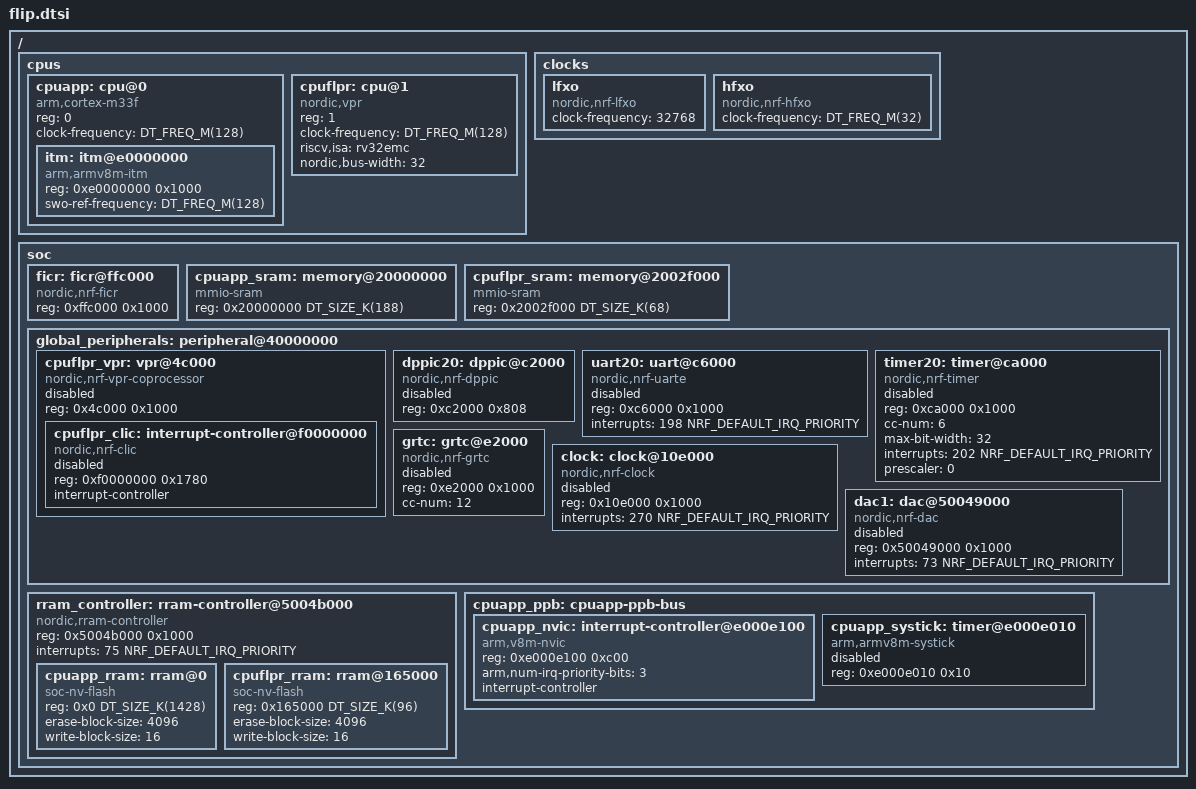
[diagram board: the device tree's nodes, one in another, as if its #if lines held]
/*
 * Copyright (c) 2024 Nordic Semiconductor ASA
 *
 * SPDX-License-Identifier: Apache-2.0
 */

#include <mem.h>
#include <nordic/nrf_common.dtsi>

/delete-node/ &sw_pwm;

/* Domain IDs. Can be used to specify channel links in IPCT nodes. */
#define NRF_DOMAIN_ID_APPLICATION 0
#define NRF_DOMAIN_ID_FLPR 1

/ {
	#address-cells = <1>;
	#size-cells = <1>;

	cpus {
		#address-cells = <1>;
		#size-cells = <0>;

		cpuapp: cpu@0 {
			compatible = "arm,cortex-m33f";
			reg = <0>;
			device_type = "cpu";
			clock-frequency = <DT_FREQ_M(128)>;
			#address-cells = <1>;
			#size-cells = <1>;
			itm: itm@e0000000 {
				compatible = "arm,armv8m-itm";
				reg = <0xe0000000 0x1000>;
				swo-ref-frequency = <DT_FREQ_M(128)>;
			};
		};

		cpuflpr: cpu@1 {
			compatible = "nordic,vpr";
			reg = <1>;
			device_type = "cpu";
			clock-frequency = <DT_FREQ_M(128)>;
			riscv,isa = "rv32emc";
			nordic,bus-width = <32>;
		};
	};

	clocks {
		lfxo: lfxo {
			compatible = "nordic,nrf-lfxo";
			#clock-cells = <0>;
			clock-frequency = <32768>;
		};

		hfxo: hfxo {
			compatible = "nordic,nrf-hfxo";
			#clock-cells = <0>;
			clock-frequency = <DT_FREQ_M(32)>;
		};
	};

	soc {
		#address-cells = <1>;
		#size-cells = <1>;

#ifdef USE_NON_SECURE_ADDRESS_MAP
		/* intentionally empty because UICR is hardware fixed to Secure */
#else
		uicr: uicr@ffd000 {
			compatible = "nordic,nrf-uicr";
			reg = <0xffd000 0x1000>;
		};
#endif
		ficr: ficr@ffc000 {
			compatible = "nordic,nrf-ficr";
			reg = <0xffc000 0x1000>;
			#nordic,ficr-cells = <1>;
		};

		cpuapp_sram: memory@20000000 {
			compatible = "mmio-sram";
			reg = <0x20000000 DT_SIZE_K(188)>;
			#address-cells = <1>;
			#size-cells = <1>;
			ranges = <0x0 0x20000000 0x2f000>;
		};

		cpuflpr_sram: memory@2002f000 {
			compatible = "mmio-sram";
			reg = <0x2002f000 DT_SIZE_K(68)>;
			#address-cells = <1>;
			#size-cells = <1>;
			ranges = <0x0 0x2002f000 0x11000>;
		};

#ifdef USE_NON_SECURE_ADDRESS_MAP
		global_peripherals: peripheral@40000000 {
			#address-cells = <1>;
			#size-cells = <1>;
			ranges = <0x0 0x40000000 0x10000000>;
#else
		global_peripherals: peripheral@50000000 {
			#address-cells = <1>;
			#size-cells = <1>;
			ranges = <0x0 0x50000000 0x10000000>;
#endif
			cpuflpr_vpr: vpr@4c000 {
				compatible = "nordic,nrf-vpr-coprocessor";
				reg = <0x4c000 0x1000>;
				ranges = <0x0 0x4c000 0x1000>;
				#address-cells = <1>;
				#size-cells = <1>;
				status = "disabled";

				cpuflpr_clic: interrupt-controller@f0000000 {
					compatible = "nordic,nrf-clic";
					reg = <0xf0000000 0x1780>;
					interrupt-controller;
					#interrupt-cells = <2>;
					#address-cells = <1>;
					status = "disabled";
				};
			};

			dppic20: dppic@c2000 {
				compatible = "nordic,nrf-dppic";
				reg = <0xc2000 0x808>;
				status = "disabled";
			};

			uart20: uart@c6000 {
				compatible = "nordic,nrf-uarte";
				reg = <0xc6000 0x1000>;
				interrupts = <198 NRF_DEFAULT_IRQ_PRIORITY>;
				status = "disabled";
			};

			timer20: timer@ca000 {
				compatible = "nordic,nrf-timer";
				status = "disabled";
				reg = <0xca000 0x1000>;
				cc-num = <6>;
				max-bit-width = <32>;
				interrupts = <202 NRF_DEFAULT_IRQ_PRIORITY>;
				prescaler = <0>;
			};

			grtc: grtc@e2000 {
				compatible = "nordic,nrf-grtc";
				reg = <0xe2000 0x1000>;
				cc-num = <12>;
				status = "disabled";
			};

			clock: clock@10e000 {
				compatible = "nordic,nrf-clock";
				reg = <0x10e000 0x1000>;
				interrupts = <270 NRF_DEFAULT_IRQ_PRIORITY>;
				status = "disabled";
			};

			dac1: dac@50049000 {
				compatible = "nordic,nrf-dac";
				reg = <0x50049000 0x1000>;
				interrupts = <73 NRF_DEFAULT_IRQ_PRIORITY>;
				status = "disabled";
				#io-channel-cells = <1>;
			};
		};

		rram_controller: rram-controller@5004b000 {
			compatible = "nordic,rram-controller";
			reg = <0x5004b000 0x1000>;
			#address-cells = <1>;
			#size-cells = <1>;
			interrupts = <75 NRF_DEFAULT_IRQ_PRIORITY>;

			cpuapp_rram: rram@0 {
				compatible = "soc-nv-flash";
				reg = <0x0 DT_SIZE_K(1428)>;
				erase-block-size = <4096>;
				write-block-size = <16>;
			};
			cpuflpr_rram: rram@165000 {
				compatible = "soc-nv-flash";
				reg = <0x165000 DT_SIZE_K(96)>;
				erase-block-size = <4096>;
				write-block-size = <16>;
			};
		};

		cpuapp_ppb: cpuapp-ppb-bus {
			#address-cells = <1>;
			#size-cells = <1>;

			cpuapp_nvic: interrupt-controller@e000e100  {
				#address-cells = <1>;
				compatible = "arm,v8m-nvic";
				reg = <0xe000e100 0xc00>;
				arm,num-irq-priority-bits = <3>;
				interrupt-controller;
				#interrupt-cells = <2>;
			};

			cpuapp_systick: timer@e000e010 {
				compatible = "arm,armv8m-systick";
				reg = <0xe000e010 0x10>;
				status = "disabled";
			};
		};
	};
};
